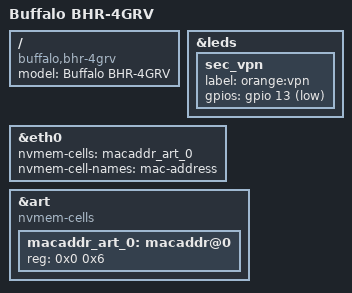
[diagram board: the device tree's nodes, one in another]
// SPDX-License-Identifier: GPL-2.0-or-later OR MIT

#include "ar7242_buffalo_wzr-bhr.dtsi"

/ {
	compatible = "buffalo,bhr-4grv", "qca,ar7242";
	model = "Buffalo BHR-4GRV";
};

&leds {
	sec_vpn {
		label = "orange:vpn";
		gpios = <&gpio 13 GPIO_ACTIVE_LOW>;
	};
};

&eth0 {
	nvmem-cells = <&macaddr_art_0>;
	nvmem-cell-names = "mac-address";
};

&art {
	compatible = "nvmem-cells";
	#address-cells = <1>;
	#size-cells = <1>;

	macaddr_art_0: macaddr@0 {
		reg = <0x0 0x6>;
	};
};
